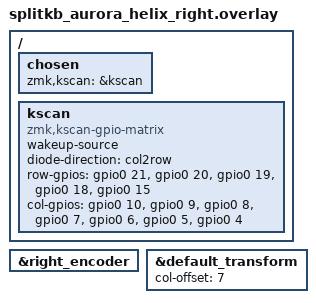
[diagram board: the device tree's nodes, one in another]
/ {
    chosen {
        zmk,kscan = &kscan;
    };
    kscan: kscan {
        compatible = "zmk,kscan-gpio-matrix";
        wakeup-source;
        diode-direction = "col2row";
        row-gpios = <
            &gpio0 21 (GPIO_PULL_DOWN | GPIO_ACTIVE_HIGH),
            &gpio0 20 (GPIO_PULL_DOWN | GPIO_ACTIVE_HIGH),
            &gpio0 19 (GPIO_PULL_DOWN | GPIO_ACTIVE_HIGH),
            &gpio0 18 (GPIO_PULL_DOWN | GPIO_ACTIVE_HIGH),
            &gpio0 15 (GPIO_PULL_DOWN | GPIO_ACTIVE_HIGH)
        >;
        col-gpios = <
            &gpio0 10 GPIO_ACTIVE_HIGH,
            &gpio0 9  GPIO_ACTIVE_HIGH,
            &gpio0 8  GPIO_ACTIVE_HIGH,
            &gpio0 7  GPIO_ACTIVE_HIGH,
            &gpio0 6  GPIO_ACTIVE_HIGH,
            &gpio0 5  GPIO_ACTIVE_HIGH,
            &gpio0 4  GPIO_ACTIVE_HIGH
        >;
    };
};
&right_encoder {
    status = "okay";
};
&default_transform {
    col-offset = <7>;
};
